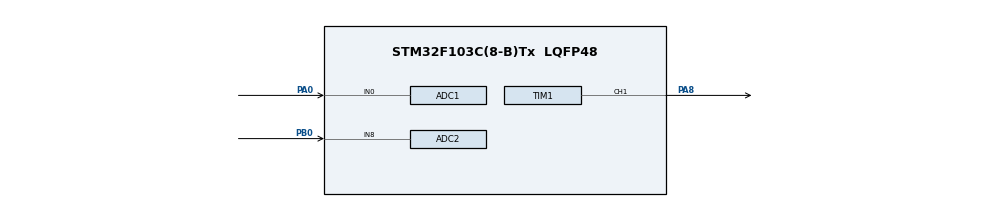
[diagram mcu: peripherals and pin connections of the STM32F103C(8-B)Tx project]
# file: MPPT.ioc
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ADC1.Channel-0\#ChannelRegularConversion=ADC_CHANNEL_0
ADC1.NbrOfConversionFlag=1
ADC1.Rank-0\#ChannelRegularConversion=1
ADC1.SamplingTime-0\#ChannelRegularConversion=ADC_SAMPLETIME_1CYCLE_5
ADC1.master=1
ADC2.Channel-1\#ChannelRegularConversion=ADC_CHANNEL_8
ADC2.NbrOfConversionFlag=1
ADC2.Rank-1\#ChannelRegularConversion=1
ADC2.SamplingTime-1\#ChannelRegularConversion=ADC_SAMPLETIME_1CYCLE_5
Mcu.Family=STM32F1
Mcu.Name=STM32F103C(8-B)Tx
Mcu.Package=LQFP48
NVIC.PriorityGroup=NVIC_PRIORITYGROUP_4
PA0-WKUP.Signal=ADCx_IN0
PA13.Mode=JTAG_4_pins
PA13.Signal=SYS_JTMS-SWDIO
PA14.Mode=JTAG_4_pins
PA14.Signal=SYS_JTCK-SWCLK
PA15.Mode=JTAG_4_pins
PA15.Signal=SYS_JTDI
PA8.Signal=S_TIM1_CH1
PB0.Signal=ADCx_IN8
PB3.Mode=JTAG_4_pins
PB3.Signal=SYS_JTDO-TRACESWO
ProjectManager.HeapSize=0x200
ProjectManager.StackSize=0x400
ProjectManager.TargetToolchain=STM32CubeIDE
RCC.APB1Freq_Value=8000000
RCC.APB2Freq_Value=8000000
RCC.USBFreq_Value=8000000
SH.ADCx_IN0.0=ADC1_IN0,IN0
SH.ADCx_IN8.0=ADC2_IN8,IN8
SH.S_TIM1_CH1.0=TIM1_CH1,PWM Generation1 CH1
TIM1.Channel-PWM\ Generation1\ CH1=TIM_CHANNEL_1
TIM1.Period=50
TIM1.Prescaler=0
VP_TIM1_VS_ClockSourceINT.Mode=Internal
board=custom

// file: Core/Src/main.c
/* USER CODE BEGIN Header */
/**
  ******************************************************************************
  * @file           : main.c
  * @brief          : Main program body
  ******************************************************************************
  * @attention
  *
  * <h2><center>&copy; Copyright (c) 2020 STMicroelectronics.
  * All rights reserved.</center></h2>
  *
  * This software component is licensed by ST under BSD 3-Clause license,
  * the "License"; You may not use this file except in compliance with the
  * License. You may obtain a copy of the License at:
  *                        opensource.org/licenses/BSD-3-Clause
  *
  ******************************************************************************
  */
/* USER CODE END Header */

#include "main.h"

/* USER CODE BEGIN Includes */
#include <stdio.h>

/* USER CODE END Includes */

ADC_HandleTypeDef hadc1;
ADC_HandleTypeDef hadc2;

TIM_HandleTypeDef htim1;

void SystemClock_Config(void);
static void MX_GPIO_Init(void);
static void MX_ADC1_Init(void);
static void MX_ADC2_Init(void);
static void MX_TIM1_Init(void);

int main(void)
{

  /* MCU Configuration--------------------------------------------------------*/

  /* Reset of all peripherals, Initializes the Flash interface and the Systick. */
  HAL_Init();

  /* Configure the system clock */
  SystemClock_Config();

  /* Initialize all configured peripherals */
  MX_GPIO_Init();
  MX_ADC1_Init();
  MX_ADC2_Init();
  MX_TIM1_Init();
  /* USER CODE BEGIN 2 */
  HAL_TIM_PWM_Start(&htim1, TIM_CHANNEL_1);
  double volt_old = 0;
  double volt_bit = 0;
  double volt_new  = 0;
  double curr_new = 0;
  double curr_bit = 0;
  double curr_old = 0;

  double pow_old = 0;
  double pow_new = 0;
  uint16_t dutyC = 0;

  /* USER CODE END 2 */

  /* Infinite loop */
  /* USER CODE BEGIN WHILE */
  while (1)
  {

	 if (dutyC == 0) {
		dutyC = 5;
		htim1.Instance->CCR1 = dutyC;
		HAL_ADC_Start(&hadc1);
		HAL_ADC_PollForConversion(&hadc1, 1000);
		volt_bit = HAL_ADC_GetValue(&hadc1);
		volt_old = volt_bit/4096*33;
		HAL_ADC_Start(&hadc2);
		HAL_ADC_PollForConversion(&hadc2, 1000);
		curr_bit = HAL_ADC_GetValue(&hadc2);
		curr_old = curr_bit/4096*3.3;
		pow_old = volt_old*curr_old;
		dutyC += 1;
		htim1.Instance->CCR1 = dutyC;
		HAL_ADC_Start(&hadc1);
		HAL_ADC_PollForConversion(&hadc1, 1000);
		volt_bit = HAL_ADC_GetValue(&hadc1);
		volt_new = volt_bit/4096*33;
		HAL_ADC_Start(&hadc2);
		HAL_ADC_PollForConversion(&hadc2, 1000);
		curr_bit = HAL_ADC_GetValue(&hadc2);
		curr_new = curr_bit/4096*3.3;
		pow_new = volt_old*curr_old;

	 }
	 else {
		HAL_ADC_Start(&hadc1);
		HAL_ADC_PollForConversion(&hadc1, 1000);
		volt_bit = HAL_ADC_GetValue(&hadc1);
		volt_new = volt_bit/4096*33;
		HAL_ADC_Start(&hadc2);
		HAL_ADC_PollForConversion(&hadc2, 1000);
		curr_bit = HAL_ADC_GetValue(&hadc2);
		curr_new = curr_bit/4096*3.3;
		pow_new = volt_old*curr_old;
	 }
     if (pow_new > pow_old){
        if(volt_new > volt_old && curr_new < .3){
        	//dutyC += 1;
        }
        else {
        	//dutyC -= 1;
        }
     }
     if (pow_new < pow_old){
    	 if (volt_new < volt_old && curr_new < .3){
    		 //dutyC += 1;
    	 }
    	 else {
    		//dutyC -= 1;
    	 }
     }
     htim1.Instance->CCR1 = dutyC;
     pow_old = pow_new;
     volt_old = volt_new;
     curr_old = curr_new;

    /* USER CODE END WHILE */

  }
}

void SystemClock_Config(void)
{
  RCC_OscInitTypeDef RCC_OscInitStruct = {0};
  RCC_ClkInitTypeDef RCC_ClkInitStruct = {0};
  RCC_PeriphCLKInitTypeDef PeriphClkInit = {0};

  /** Initializes the CPU, AHB and APB busses clocks
  */
  RCC_OscInitStruct.OscillatorType = RCC_OSCILLATORTYPE_HSI;
  RCC_OscInitStruct.HSIState = RCC_HSI_ON;
  RCC_OscInitStruct.HSICalibrationValue = RCC_HSICALIBRATION_DEFAULT;
  RCC_OscInitStruct.PLL.PLLState = RCC_PLL_NONE;
  if (HAL_RCC_OscConfig(&RCC_OscInitStruct) != HAL_OK)
  {
    Error_Handler();
  }
  /** Initializes the CPU, AHB and APB busses clocks
  */
  RCC_ClkInitStruct.ClockType = RCC_CLOCKTYPE_HCLK|RCC_CLOCKTYPE_SYSCLK
                              |RCC_CLOCKTYPE_PCLK1|RCC_CLOCKTYPE_PCLK2;
  RCC_ClkInitStruct.SYSCLKSource = RCC_SYSCLKSOURCE_HSI;
  RCC_ClkInitStruct.AHBCLKDivider = RCC_SYSCLK_DIV1;
  RCC_ClkInitStruct.APB1CLKDivider = RCC_HCLK_DIV1;
  RCC_ClkInitStruct.APB2CLKDivider = RCC_HCLK_DIV1;

  if (HAL_RCC_ClockConfig(&RCC_ClkInitStruct, FLASH_LATENCY_0) != HAL_OK)
  {
    Error_Handler();
  }
  PeriphClkInit.PeriphClockSelection = RCC_PERIPHCLK_ADC;
  PeriphClkInit.AdcClockSelection = RCC_ADCPCLK2_DIV2;
  if (HAL_RCCEx_PeriphCLKConfig(&PeriphClkInit) != HAL_OK)
  {
    Error_Handler();
  }
}

static void MX_ADC1_Init(void)
{

  ADC_ChannelConfTypeDef sConfig = {0};

  /** Common config
  */
  hadc1.Instance = ADC1;
  hadc1.Init.ScanConvMode = ADC_SCAN_DISABLE;
  hadc1.Init.ContinuousConvMode = DISABLE;
  hadc1.Init.DiscontinuousConvMode = DISABLE;
  hadc1.Init.ExternalTrigConv = ADC_SOFTWARE_START;
  hadc1.Init.DataAlign = ADC_DATAALIGN_RIGHT;
  hadc1.Init.NbrOfConversion = 1;
  if (HAL_ADC_Init(&hadc1) != HAL_OK)
  {
    Error_Handler();
  }
  /** Configure Regular Channel
  */
  sConfig.Channel = ADC_CHANNEL_0;
  sConfig.Rank = ADC_REGULAR_RANK_1;
  sConfig.SamplingTime = ADC_SAMPLETIME_1CYCLE_5;
  if (HAL_ADC_ConfigChannel(&hadc1, &sConfig) != HAL_OK)
  {
    Error_Handler();
  }

}

static void MX_ADC2_Init(void)
{

  ADC_ChannelConfTypeDef sConfig = {0};

  /** Common config
  */
  hadc2.Instance = ADC2;
  hadc2.Init.ScanConvMode = ADC_SCAN_DISABLE;
  hadc2.Init.ContinuousConvMode = DISABLE;
  hadc2.Init.DiscontinuousConvMode = DISABLE;
  hadc2.Init.ExternalTrigConv = ADC_SOFTWARE_START;
  hadc2.Init.DataAlign = ADC_DATAALIGN_RIGHT;
  hadc2.Init.NbrOfConversion = 1;
  if (HAL_ADC_Init(&hadc2) != HAL_OK)
  {
    Error_Handler();
  }
  /** Configure Regular Channel
  */
  sConfig.Channel = ADC_CHANNEL_8;
  sConfig.Rank = ADC_REGULAR_RANK_1;
  sConfig.SamplingTime = ADC_SAMPLETIME_1CYCLE_5;
  if (HAL_ADC_ConfigChannel(&hadc2, &sConfig) != HAL_OK)
  {
    Error_Handler();
  }

}

static void MX_TIM1_Init(void)
{

  TIM_ClockConfigTypeDef sClockSourceConfig = {0};
  TIM_MasterConfigTypeDef sMasterConfig = {0};
  TIM_OC_InitTypeDef sConfigOC = {0};
  TIM_BreakDeadTimeConfigTypeDef sBreakDeadTimeConfig = {0};

  htim1.Instance = TIM1;
  htim1.Init.Prescaler = 0;
  htim1.Init.CounterMode = TIM_COUNTERMODE_UP;
  htim1.Init.Period = 50;
  htim1.Init.ClockDivision = TIM_CLOCKDIVISION_DIV1;
  htim1.Init.RepetitionCounter = 0;
  htim1.Init.AutoReloadPreload = TIM_AUTORELOAD_PRELOAD_DISABLE;
  if (HAL_TIM_Base_Init(&htim1) != HAL_OK)
  {
    Error_Handler();
  }
  sClockSourceConfig.ClockSource = TIM_CLOCKSOURCE_INTERNAL;
  if (HAL_TIM_ConfigClockSource(&htim1, &sClockSourceConfig) != HAL_OK)
  {
    Error_Handler();
  }
  if (HAL_TIM_PWM_Init(&htim1) != HAL_OK)
  {
    Error_Handler();
  }
  sMasterConfig.MasterOutputTrigger = TIM_TRGO_RESET;
  sMasterConfig.MasterSlaveMode = TIM_MASTERSLAVEMODE_DISABLE;
  if (HAL_TIMEx_MasterConfigSynchronization(&htim1, &sMasterConfig) != HAL_OK)
  {
    Error_Handler();
  }
  sConfigOC.OCMode = TIM_OCMODE_PWM1;
  sConfigOC.Pulse = 0;
  sConfigOC.OCPolarity = TIM_OCPOLARITY_HIGH;
  sConfigOC.OCNPolarity = TIM_OCNPOLARITY_HIGH;
  sConfigOC.OCFastMode = TIM_OCFAST_DISABLE;
  sConfigOC.OCIdleState = TIM_OCIDLESTATE_RESET;
  sConfigOC.OCNIdleState = TIM_OCNIDLESTATE_RESET;
  if (HAL_TIM_PWM_ConfigChannel(&htim1, &sConfigOC, TIM_CHANNEL_1) != HAL_OK)
  {
    Error_Handler();
  }
  sBreakDeadTimeConfig.OffStateRunMode = TIM_OSSR_DISABLE;
  sBreakDeadTimeConfig.OffStateIDLEMode = TIM_OSSI_DISABLE;
  sBreakDeadTimeConfig.LockLevel = TIM_LOCKLEVEL_OFF;
  sBreakDeadTimeConfig.DeadTime = 0;
  sBreakDeadTimeConfig.BreakState = TIM_BREAK_DISABLE;
  sBreakDeadTimeConfig.BreakPolarity = TIM_BREAKPOLARITY_HIGH;
  sBreakDeadTimeConfig.AutomaticOutput = TIM_AUTOMATICOUTPUT_DISABLE;
  if (HAL_TIMEx_ConfigBreakDeadTime(&htim1, &sBreakDeadTimeConfig) != HAL_OK)
  {
    Error_Handler();
  }
  HAL_TIM_MspPostInit(&htim1);

}

static void MX_GPIO_Init(void)
{

  /* GPIO Ports Clock Enable */
  __HAL_RCC_GPIOA_CLK_ENABLE();
  __HAL_RCC_GPIOB_CLK_ENABLE();

}

void Error_Handler(void)
{
}

/************************ (C) COPYRIGHT STMicroelectronics *****END OF FILE****/
